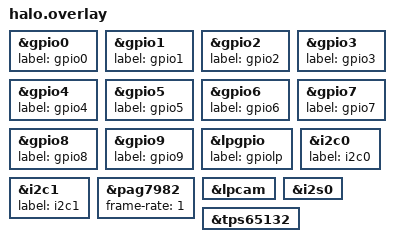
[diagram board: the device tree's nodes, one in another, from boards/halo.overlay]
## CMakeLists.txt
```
# Copyright (C) 2023 Alif Semiconductor - All Rights Reserved.
# Use, distribution and modification of this code is permitted under the
# terms stated in the Alif Semiconductor Software License Agreement
#
# You should have received a copy of the Alif Semiconductor Software
# License Agreement with this file. If not, please write to:
# contact@alifsemi.com, or visit: https://alifsemi.com/license

cmake_minimum_required(VERSION 3.20.0)
find_package(Zephyr REQUIRED HINTS $ENV{ZEPHYR_BASE})
project(halo)


FILE(GLOB app_sources src/*c)
target_sources(app PRIVATE ${app_sources})

libmpix_init(app)
```

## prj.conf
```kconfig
CONFIG_LOG=y
CONFIG_PRINTK=y
CONFIG_ASSERT=y
CONFIG_STDOUT_CONSOLE=y
CONFIG_SHELL=y
CONFIG_GPIO=y
CONFIG_GPIO_SHELL=y
CONFIG_I2C=y
CONFIG_REGULATOR=y
CONFIG_REGULATOR_SHELL=y
CONFIG_I2C_SHELL=y
CONFIG_SENSOR=y
CONFIG_SENSOR_SHELL=y
CONFIG_ADC=y
CONFIG_ADC_SHELL=y
CONFIG_FILE_SYSTEM=y
CONFIG_FILE_SYSTEM_LITTLEFS=y
CONFIG_FILE_SYSTEM_SHELL=y
CONFIG_SETTINGS_FILE_PATH="/lfs/settings"


CONFIG_MAIN_STACK_SIZE=4096
CONFIG_IDLE_STACK_SIZE=4096
CONFIG_ISR_STACK_SIZE=4096

CONFIG_PM=y
CONFIG_PM_DEVICE=y
CONFIG_COUNTER=y
CONFIG_COUNTER_RTC_SNPS_DW=y
CONFIG_COUNTER_SNPS_DW=y
```

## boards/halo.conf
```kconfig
CONFIG_I2C_DW=y
CONFIG_I2C_TARGET=y
CONFIG_I2C=y
CONFIG_I2C_DW_CLOCK_SPEED=40

# Flash layout
CONFIG_XIP=y
CONFIG_FLASH=y
CONFIG_FLASH_MAP=y
CONFIG_FLASH_PAGE_LAYOUT=y
CONFIG_MPU_ALLOW_FLASH_WRITE=y
CONFIG_HEAP_MEM_POOL_SIZE=65536

#Microphone & Speaker
CONFIG_I2S=y
CONFIG_AUDIO=y
CONFIG_MAX98357A_AUDIO=y
CONFIG_MAX98357A_AUDIO_GENERIC_API=y
CONFIG_T5838_AAD_TRIGGER=y

#Display
CONFIG_DISPLAY=y
CONFIG_CDC200=y
CONFIG_MIPI_DSI=y
CONFIG_CANVAS=y
CONFIG_FB_USES_DTCM_REGION=y

# LED
CONFIG_PWM=y
CONFIG_LED_PWM=y
CONFIG_LED_INIT_PRIORITY=50

# Camera
CONFIG_VIDEO=y
CONFIG_VIDEO_MIPI_CSI2_DW=n
CONFIG_VIDEO_BUFFER_POOL_NUM_MAX=1
CONFIG_VIDEO_BUFFER_POOL_SZ_MAX=327680
CONFIG_FB_USES_DTCM_REGION=y
CONFIG_MPIX=y
CONFIG_MPIX_HEAP_SIZE=65536

# BLE
CONFIG_BT=y
CONFIG_BT_CUSTOM=y
```

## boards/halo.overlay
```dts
/* label for it */

&gpio0 {
	label = "gpio0";
};
&gpio1 {
	label = "gpio1";
};
&gpio2 {
	label = "gpio2";
};
&gpio3 {
	label = "gpio3";
};
&gpio4 {
	label = "gpio4";
};
&gpio5 {
	label = "gpio5";
};
&gpio6 {
	label = "gpio6";
};
&gpio7 {
	label = "gpio7";
};
&gpio8 {
	label = "gpio8";
};
&gpio9 {
	label = "gpio9";
};
&lpgpio {
	label = "gpiolp";
};
&i2c0{
    label = "i2c0";
};
&i2c1{
    label = "i2c1";
};


&pag7982{
	status = "okay";
	frame-rate = <1>;
};

&lpcam {
	status = "okay";
};

&i2s0 {
	status = "okay";
};

/* The display (vga020) takes its rails from this PMIC; the board leaves it disabled. */
&tps65132 {
	status = "okay";
};
```

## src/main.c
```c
#include <errno.h>
#include <stddef.h>
#include <stdlib.h>
#include <string.h>

#include <zephyr/sys/printk.h>
#include <zephyr/sys/byteorder.h>
#include <zephyr/kernel.h>
#include <zephyr/drivers/gpio.h>
#include <zephyr/drivers/input/button.h>
//#include <t5838.h>

void button_event_cb(const struct device *dev, enum button_action action)
{
	switch (action) {
	case BUTTON_SINGLE_CLICK:
		printf("\nSingle Click: %d\n", k_uptime_get_32());
		break;
	case BUTTON_DOUBLE_CLICK:
		printf("\nDouble Click: %d\n", k_uptime_get_32());
		break;
	case BUTTON_LONG_PRESS:
		printf("\nLong Press: %d\n", k_uptime_get_32());
		break;
	case BUTTON_LONG_PRESS_LEVEL_1:
		printf("\nLong Press Level 1: %d\n", k_uptime_get_32());
		break;
	case BUTTON_LONG_PRESS_LEVEL_2:
		printf("\nLong Press Level 2: %d\n", k_uptime_get_32());
		break;
	case BUTTON_LONG_PRESS_LEVEL_3:
		printf("\nLong Press Level 3: %d\n", k_uptime_get_32());
		break;
	default:
		break;
	}
}

void t5838_cb(const struct device *dev)
{
	printf("\nT5838 interrupt triggered\n");
}

int main(void)
{
	const struct device *button = DEVICE_DT_GET(DT_ALIAS(sw0));

	button_callback_register(button, button_event_cb);

	// const struct device *t5838 = DEVICE_DT_GET(DT_NODELABEL(t5838));

	// /*AAD A CONFIGURATION */
	// struct t5838_aad_a_conf aadcfg = {
	// 	.aad_a_lpf = T5838_AAD_A_LPF_2_0kHz,
	// 	.aad_a_thr = T5838_AAD_A_THR_90dB,
	// 	.silent_period = 1000,
	// };
	// t5838_aad_a_mode_set(t5838, &aadcfg);
	// t5838_aad_wake_handler_set(t5838, t5838_cb);

	while (1) {
		k_sleep(K_SECONDS(1));
	}
	return 0;
}
```

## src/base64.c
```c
#include <math.h>
#include <string.h>

#include <zephyr/sys/util.h>

#include "base64.h"


static const char *base64_chars = "ABCDEFGHIJKLMNOPQRSTUVWXYZ"
                                  "abcdefghijklmnopqrstuvwxyz"
                                  "0123456789+/";

/**
 * @brief Base64 encode and write to a putc function
 *
 * @param input
 * @param input_size
 * @param putc_f pointer to putc function
 */
void base64_encode(const char *input, size_t input_size, void (*putc_f)(char))
{
    int i = 0;
    int j = 0;
    unsigned char char_array_3[3];
    unsigned char char_array_4[4];

    while (input_size--) {
        char_array_3[i++] = *(input++);
        if (i == 3) {
            char_array_4[0] = (char_array_3[0] & 0xfc) >> 2;
            char_array_4[1] = ((char_array_3[0] & 0x03) << 4) + ((char_array_3[1] & 0xf0) >> 4);
            char_array_4[2] = ((char_array_3[1] & 0x0f) << 2) + ((char_array_3[2] & 0xc0) >> 6);
            char_array_4[3] = char_array_3[2] & 0x3f;

            for (i = 0; (i < 4); i++) {
                putc_f(base64_chars[char_array_4[i]]);
            }
            i = 0;
        }
    }

    if (i) {
        for (j = i; j < 3; j++) {
            char_array_3[j] = '\0';
        }

        char_array_4[0] = (char_array_3[0] & 0xfc) >> 2;
        char_array_4[1] = ((char_array_3[0] & 0x03) << 4) + ((char_array_3[1] & 0xf0) >> 4);
        char_array_4[2] = ((char_array_3[1] & 0x0f) << 2) + ((char_array_3[2] & 0xc0) >> 6);
        char_array_4[3] = char_array_3[2] & 0x3f;

        for (j = 0; (j < i + 1); j++) {
            putc_f(base64_chars[char_array_4[j]]);
        }

        while ((i++ < 3)) {
            putc_f('=');
        }
    }
}

void base64_encode_chunk(const char *input, size_t input_size, void (*putc_f)(char))
{
    static char leftover[3];
    static uint8_t leftover_size = 0;

    if (input == NULL) {
        base64_encode(leftover, leftover_size, putc_f);
        leftover_size = 0;
        return;
    }

    // if we have leftover bytes, try to get N bytes from input
    // to fulfill 3 bytes chunk from base64 encoder
    if (leftover_size > 0) {
        // in case input_size is 1B and we have 1B leftover
        uint8_t to_copy = MIN((size_t)(3 - leftover_size), input_size);
        memcpy(&leftover[leftover_size], input, to_copy);
        leftover_size += to_copy;
        // if we hve not enough data to encode, break
        if (leftover_size < 3) {
            return;
        }
        base64_encode(leftover, leftover_size, putc_f);
        leftover_size = 0;
        input_size -= to_copy;
        input += to_copy;
    }

    if (input_size % 3 == 0) {
        base64_encode(input, input_size, putc_f);
    }
    else {
        leftover_size = input_size % 3;
        base64_encode(input, input_size - leftover_size, putc_f);
        memcpy(leftover, &input[input_size - leftover_size], leftover_size);
    }
}

void base64_encode_finish(void (*putc_f)(char))
{
    base64_encode_chunk(NULL, 0, putc_f);
}

/**
 * @brief Base64 encode and write to output buffer, errors on buffer overflow
 *
 * @param input
 * @param input_size
 * @param output
 * @param output_size
 * @return int number of bytes in output buffer, negative if error occured
 */
int base64_encode_buffer(const char *input, size_t input_size, char *output, size_t output_size)
{
    size_t output_size_check = floor(input_size / 3 * 4);
    size_t mod = input_size % 3;
    output_size_check += mod;

    if (output_size < output_size_check) {
        return -10;
    }

    int i = 0;
    int j = 0;
    unsigned char char_array_3[3];
    unsigned char char_array_4[4];
    size_t output_ix = 0;

    while (input_size--) {
        char_array_3[i++] = *(input++);
        if (i == 3) {
            char_array_4[0] = (char_array_3[0] & 0xfc) >> 2;
            char_array_4[1] = ((char_array_3[0] & 0x03) << 4) + ((char_array_3[1] & 0xf0) >> 4);
            char_array_4[2] = ((char_array_3[1] & 0x0f) << 2) + ((char_array_3[2] & 0xc0) >> 6);
            char_array_4[3] = char_array_3[2] & 0x3f;

            for (i = 0; (i < 4); i++) {
                output[output_ix++] = base64_chars[char_array_4[i]];
            }
            i = 0;
        }
    }

    if (i) {
        for (j = i; j < 3; j++) {
            char_array_3[j] = '\0';
        }

        char_array_4[0] = (char_array_3[0] & 0xfc) >> 2;
        char_array_4[1] = ((char_array_3[0] & 0x03) << 4) + ((char_array_3[1] & 0xf0) >> 4);
        char_array_4[2] = ((char_array_3[1] & 0x0f) << 2) + ((char_array_3[2] & 0xc0) >> 6);
        char_array_4[3] = char_array_3[2] & 0x3f;

        for (j = 0; (j < i + 1); j++) {
            output[output_ix++] = base64_chars[char_array_4[j]];
        }

        while ((i++ < 3)) {
            output[output_ix++] = '=';
        }
    }

    return output_ix;
}
```

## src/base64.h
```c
#ifndef BASE64_H
#define BASE64_H

#include <stddef.h>
#include <stdint.h>

void base64_encode(const char *input, size_t input_size, void (*putc_f)(char));
void base64_encode_chunk(const char *input, size_t input_size, void (*putc_f)(char));
void base64_encode_finish(void (*putc_f)(char));
int base64_encode_buffer(const char *input, size_t input_size, char *output, size_t output_size);

#endif
```

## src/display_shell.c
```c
#include <string.h>
#include <stdlib.h>

#include <zephyr/kernel.h>
#include <zephyr/shell/shell.h>

#if CONFIG_DISPLAY
#include <zephyr/drivers/display.h>
#include <zephyr/drivers/display/cdc200.h>
#include <zephyr/drivers/mipi_dsi/dsi_dw.h>
#include <zephyr/pm/device.h>
#include <canvas.h>

static const struct device *dsi = NULL;
static const struct device *panel = NULL;
static const struct device *display = NULL;

static Canvas canvas;

static int color_index = 0;
/* Color list */
static const Color color_list[] = {
	COLOR_HEX(0xFFFFFF), // White
	COLOR_HEX(0xFF0000), // Red
	COLOR_HEX(0x00FF00), // Green
	COLOR_HEX(0x0000FF), // Blue
	COLOR_HEX(0x000000), // Black
	COLOR_HEX(0x646464), // Gray
};
#define COLOR_COUNT (sizeof(color_list) / sizeof(color_list[0]))
#define MODE_COUNT  (COLOR_COUNT + 1)

static void update_display_color(void)
{
	canvas_clear(&canvas, color_list[color_index]);
}

void draw_grayscale_pyramid(const struct shell *sh)
{
	const int cx = LOG_WIDTH / 2;  // Center X coordinate (160)
	const int cy = LOG_HEIGHT / 2; // Center Y coordinate (120)

	const int W = LOG_WIDTH;  // Logical display width (320)
	const int H = LOG_HEIGHT; // Logical display height (240)

	// Iterate through every pixel on the screen
	for (int y = 0; y < LOG_HEIGHT; y++) {
		for (int x = 0; x < LOG_WIDTH; x++) {
			int dx = abs(x - cx); // Horizontal distance to center
			int dy = abs(y - cy); // Vertical distance to center

			// Simulate pyramid height: scale and take the max
			int dist = MAX(dx * H, dy * W);

			// Normalize distance to a grayscale range [0, 255]
			int max_dist = (W / 2) * H; // Maximum possible distance (at corners)
			uint8_t gray = (uint8_t)((dist * 255) / max_dist);
			if (gray > 255) {
				gray = 255;
			}

			// Set the pixel to the computed grayscale value
			Color color = COLOR_RGB(gray, gray, gray);
			canvas_set_pixel(&canvas, x, y, color);
		}
	}

	shell_print(sh, "Pyramid-style grayscale gradient drawn (center black, corners white)");
}

static int cmd_display_draw(const struct shell *sh, size_t argc, char *argv[])
{
	int err = 0;

	ARG_UNUSED(argc);
	ARG_UNUSED(argv);

	if (!panel) {
		shell_error(sh, "No display device found");
		return -ENODEV;
	}

	color_index = (color_index - 1 + MODE_COUNT) % MODE_COUNT;
	if (color_index < COLOR_COUNT) {
		update_display_color();
		shell_print(sh, "Color changed to index %d", color_index);
	} else {
		draw_grayscale_pyramid(sh);
	}

	return err;
}

static int cmd_get_device(const struct shell *sh, size_t argc, char *argv[])
{
	int err = 0;

	ARG_UNUSED(argc);
	ARG_UNUSED(argv);

	if (!panel) {
		shell_error(sh, "No display device found");
		return -ENODEV;
	}

	shell_print(sh, "Display Device: %s", panel->name);

	return err;
}

static int cmd_display_fill(const struct shell *sh, size_t argc, char *argv[])
{
	int err = 0;
	uint32_t color = 0;
	ARG_UNUSED(argc);
	ARG_UNUSED(argv);
	if (!panel) {
		shell_error(sh, "No display device found");
		return -ENODEV;
	}

	color = strtol(argv[1], NULL, 16);

	shell_print(sh, "Fill Color %06X", color);
	canvas_clear(&canvas, COLOR_HEX(color));

	return err;
}

static int cmd_display_brightness(const struct shell *sh, size_t argc, char *argv[])
{
	int err = 0;
	uint8_t brightness = 0;
	ARG_UNUSED(argc);
	ARG_UNUSED(argv);
	if (!panel) {
		shell_error(sh, "No display device found");
		return -ENODEV;
	}
	brightness = strtol(argv[1], NULL, 10);
	// shell_print(sh, "Brightness: %d", brightness);
	display_set_brightness(panel, brightness);
	return err;
}

static int cmd_display_init(const struct shell *sh, size_t argc, char *argv[])
{
	int err = 0;
	ARG_UNUSED(argc);
	ARG_UNUSED(argv);

	panel = DEVICE_DT_GET(DT_CHOSEN(zephyr_panel));

	if (!device_is_ready(panel)) {
		shell_error(sh, "Panel device %s not ready", panel->name);
		return -1;
	}

	dsi = DEVICE_DT_GET(DT_ALIAS(mipi_dsi));
	if (!device_is_ready(dsi)) {
		shell_error(sh, "DSI device %s not ready", dsi->name);
		return -1;
	}

	display = DEVICE_DT_GET(DT_CHOSEN(zephyr_display));
	if (!device_is_ready(display)) {
		shell_error(sh, "Display device %s not ready", display->name);
		return -1;
	}

#ifdef CONFIG_PM_DEVICE
	pm_device_action_run(panel, PM_DEVICE_ACTION_RESUME);
#endif

	if (dsi_dw_set_mode(dsi, DSI_DW_VIDEO_MODE)) {
		shell_error(sh, "DSI Host controller set to video mode.");
		return -1;
	}

	cdc200_set_enable(display, true);
	struct cdc200_fb_desc layer;
	cdc200_get_framebuffer(display, 0, &layer);
	canvas_init(&canvas, (uint8_t (*)[240][3])layer.fb_addr);
	canvas_set_font(&canvas, &Dogica8px, 1);

	err = display_blanking_off(panel);

	return err;
}

static int cmd_display_on(const struct shell *sh, size_t argc, char *argv[])
{
	int err = 0;
	ARG_UNUSED(argc);
	ARG_UNUSED(argv);
	if (!panel) {
		shell_error(sh, "No display device found");
		return -ENODEV;
	}

	err = display_blanking_off(panel);

	return err;
}

static int cmd_display_off(const struct shell *sh, size_t argc, char *argv[])
{
	int err = 0;
	ARG_UNUSED(argc);
	ARG_UNUSED(argv);
	if (!panel) {
		shell_error(sh, "No display device found");
		return -ENODEV;
	}

	err = display_blanking_on(panel);

	return err;
}

static int cmd_display_deinit(const struct shell *sh, size_t argc, char *argv[])
{
	int err = 0;
	ARG_UNUSED(argc);
	ARG_UNUSED(argv);
	if (!panel) {
		shell_error(sh, "No display device found");
		return -ENODEV;
	}

	err = display_blanking_on(panel);

	cdc200_set_enable(display, false);

#ifdef CONFIG_PM_DEVICE
	pm_device_action_run(panel, PM_DEVICE_ACTION_SUSPEND);
#endif

	return err;
}

SHELL_STATIC_SUBCMD_SET_CREATE(
	sub_display,
	SHELL_CMD_ARG(get_device, NULL, "get the display device", cmd_get_device, 1, 0),
	SHELL_CMD_ARG(init, NULL, "initialize the display device", cmd_display_init, 1, 0),
	SHELL_CMD_ARG(deinit, NULL, "deinitialize the display device", cmd_display_deinit, 1, 0),
	SHELL_CMD_ARG(fill, NULL, "fill the display with a color", cmd_display_fill, 2, 0),
	SHELL_CMD_ARG(brightness, NULL, "set the brightness of the display device",
		      cmd_display_brightness, 2, 0),
	SHELL_CMD_ARG(draw, NULL, "draw and switch color", cmd_display_draw, 1, 0),
	SHELL_CMD_ARG(on, NULL, "turn on the display", cmd_display_on, 1, 0),
	SHELL_CMD_ARG(off, NULL, "turn off the display", cmd_display_off, 1, 0),

	SHELL_SUBCMD_SET_END);

SHELL_CMD_REGISTER(display, &sub_display, "Display device commands", NULL);

#endif
```

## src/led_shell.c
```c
#include <string.h>
#include <stdlib.h>

#include <zephyr/kernel.h>
#include <zephyr/shell/shell.h>

#ifdef CONFIG_LED_PWM
#include <zephyr/device.h>
#include <zephyr/devicetree.h>
#include <errno.h>
#include <zephyr/drivers/led.h>
#include <zephyr/sys/util.h>
#include <zephyr/logging/log.h>

#define LED_PWM_NODE_ID	 DT_COMPAT_GET_ANY_STATUS_OKAY(pwm_leds)

static const struct device *led_pwm = NULL;


static int cmd_get_device(const struct shell *sh, size_t argc, char *argv[])
{
	int err = 0;

	ARG_UNUSED(argc);
	ARG_UNUSED(argv);

	if (!led_pwm) {
		shell_error(sh, "No led device found");
		return -ENODEV;
	}

	shell_print(sh, "led Device: %s", led_pwm->name);

	return err;
}

static int cmd_led_init(const struct shell *sh, size_t argc, char *argv[])
{
	int err = 0;
	ARG_UNUSED(argc);
	ARG_UNUSED(argv);

	led_pwm = DEVICE_DT_GET(LED_PWM_NODE_ID);

	if (!device_is_ready(led_pwm)) {
		shell_error(sh, "led_pwm device %s not ready", led_pwm->name);
		return -1;
	}

	return err;
}

static int cmd_led_brightness(const struct shell *sh, size_t argc, char *argv[])
{
	int err = 0;
	uint8_t brightness = 0;

	ARG_UNUSED(argc);
	ARG_UNUSED(argv);

	if (!led_pwm) {
		shell_error(sh, "No led device found");
		return -ENODEV;
	}

	brightness = strtol(argv[1], NULL, 10);
	shell_print(sh, "Brightness: %d", brightness);
	led_set_brightness(led_pwm, 0, brightness);

	return err;
}

SHELL_STATIC_SUBCMD_SET_CREATE(
	sub_led,
	SHELL_CMD_ARG(get_device, NULL, "get the led device", cmd_get_device, 1, 0),
	SHELL_CMD_ARG(init, NULL, "initialize the led device", cmd_led_init, 1, 0),
	SHELL_CMD_ARG(brightness, NULL, "set the brightness of the led device",
		      cmd_led_brightness, 2, 0),
	SHELL_SUBCMD_SET_END);

SHELL_CMD_REGISTER(led, &sub_led, "led device commands", NULL);

#endif
```

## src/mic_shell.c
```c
#include <string.h>
#include <stdlib.h>

#include <zephyr/kernel.h>
#include <zephyr/shell/shell.h>

#ifdef CONFIG_AUDIO
#include <zephyr/audio/dmic.h>
#include <t5838.h>

#define MICPHONE_NODE DT_CHOSEN(zephyr_micphone)

#if !DT_NODE_HAS_STATUS(MICPHONE_NODE, okay)
#error "Unsupported board: micphone devicetree node is not defined"
#endif

static const struct device *dev = DEVICE_DT_GET(MICPHONE_NODE);

static k_tid_t tid;
static struct k_thread micphone_thread;
static K_THREAD_STACK_DEFINE(micphone_thread_stack, 1024);
static bool is_initialized = false;
static bool is_recording = false;

#define PDM_SAMPLE_RATE  8000
#define SAMPLE_BIT_WIDTH 16
#define NUM_CHANNELS     2
#define DURATION_MS      5000
#define INTERVAL_MS      100 // 100ms interval
#define PDM_CHANNELS     (BIT(2) | BIT(3))

#define PDM_BLOCK_SIZE      (INTERVAL_MS * PDM_SAMPLE_RATE * SAMPLE_BIT_WIDTH * NUM_CHANNELS / 8 / 1000)
#define DATA_SIZE           (PDM_BLOCK_SIZE * (DURATION_MS / INTERVAL_MS))
#define MEM_SLAB_NUM_BLOCKS (DURATION_MS / INTERVAL_MS)

// static uint8_t pdm_data[DATA_SIZE];

// every 100ms allocate a block from the slab
K_MEM_SLAB_DEFINE(mem_slab, PDM_BLOCK_SIZE, MEM_SLAB_NUM_BLOCKS, 4);

static void micphone_fill(void *arg1, void *arg2, void *arg3)
{
	ARG_UNUSED(arg2);
	ARG_UNUSED(arg3);
	int err = 0;
	const struct shell *sh = (const struct shell *)arg1;
	uint32_t data;
	void *buffer;
	while (is_recording) {
		err = dmic_read(dev, 0, &buffer, &data, 200);
		if (!is_recording) {
			break;
		}
		if (err) {
			shell_error(sh, "Failed to read PDM: %d\n", err);
			return;
		}
		// shell_print(sh, "Microphne Read %d bytes", data);
		shell_print(sh, "r: %04X %04X %04X %04X %04X", *((uint16_t *)buffer),
			    *((uint16_t *)buffer + 1), *((uint16_t *)buffer + 2),
			    *((uint16_t *)buffer + 3), *((uint16_t *)buffer + 4));
		k_mem_slab_free(&mem_slab, buffer);
	}
}

static int cmd_get_device(const struct shell *sh, size_t argc, char *argv[])
{
	int err = 0;
	ARG_UNUSED(argc);
	ARG_UNUSED(argv);
	if (!dev) {
		shell_error(sh, "No micphone device found");
		return -ENODEV;
	}
	shell_print(sh, "Speaker Device: %s", dev->name);
	return err;
}

static int cmd_micphone_init(const struct shell *sh, size_t argc, char *argv[])
{
	ARG_UNUSED(argc);
	ARG_UNUSED(argv);
	if (!dev) {
		shell_error(sh, "No micphone device found");
		return -ENODEV;
	}

	struct dmic_cfg cfg;
	struct pcm_stream_cfg stream;

	stream.pcm_width = SAMPLE_BIT_WIDTH;
	stream.pcm_rate = PDM_SAMPLE_RATE;
	stream.mem_slab = &mem_slab;
	stream.block_size = PDM_BLOCK_SIZE;

	cfg.channel.req_num_streams = 1;
	cfg.channel.req_num_chan = NUM_CHANNELS;
	cfg.channel.req_chan_map_lo = PDM_CHANNELS; // PDM channels 2 and 3
	cfg.channel.req_chan_map_hi = 0;
	cfg.streams = &stream;

	int rc = dmic_configure(dev, &cfg);
	if (rc < 0) {
		shell_error(sh, "Failed to configure PDM: %d", rc);
		return rc;
	}

	dmic_set_gain(dev, 5);

	is_initialized = true;
	is_recording = false;
	return 0;
}

static int cmd_micphone_deinit(const struct shell *sh, size_t argc, char *argv[])
{
	int err = 0;
	ARG_UNUSED(argc);
	ARG_UNUSED(argv);
	if (!dev) {
		shell_error(sh, "No micphone device found");
		return -ENODEV;
	}
	err = dmic_trigger(dev, DMIC_TRIGGER_STOP);
	if (err) {
		shell_error(sh, "Failed to start PWM audio: %d\n", err);
		return err;
	}
	is_initialized = false;
	is_recording = false;
	return 0;
}

static int cmd_micphone_record(const struct shell *sh, size_t argc, char *argv[])
{
	int err = 0;
	ARG_UNUSED(argc);
	ARG_UNUSED(argv);
	if (!dev) {
		shell_error(sh, "No micphone device found");
		return -ENODEV;
	}

	if (!is_initialized) {
		shell_error(sh, "Speaker not initialized\n");
		return 0;
	}

	if (is_recording) {
		shell_error(sh, "Already playing\n");
		return 0;
	}

	err = dmic_trigger(dev, DMIC_TRIGGER_START);
	if (err) {
		shell_error(sh, "Failed to start PWM audio: %d\n", err);
		return err;
	}

	is_recording = true;

	tid = k_thread_create(&micphone_thread, micphone_thread_stack,
			      K_THREAD_STACK_SIZEOF(micphone_thread_stack), micphone_fill, (void *)sh, NULL,
			      NULL, K_PRIO_COOP(7), 0, K_NO_WAIT);

	return 0;
}

static int cmd_micphone_stop(const struct shell *sh, size_t argc, char *argv[])
{
	int err = 0;
	ARG_UNUSED(argc);
	ARG_UNUSED(argv);
	if (!dev) {
		shell_error(sh, "No micphone device found");
		return -ENODEV;
	}

	if (!is_initialized) {
		shell_error(sh, "Speaker not initialized\n");
		return 0;
	}

	if (!is_recording) {
		shell_error(sh, "Not playing\n");
		return 0;
	}

	err = dmic_trigger(dev, DMIC_TRIGGER_STOP);
	if (err) {
		shell_error(sh, "Failed to stop PWM audio: %d\n", err);
		return err;
	}

	is_recording = false;
	return 0;
}

SHELL_STATIC_SUBCMD_SET_CREATE(
	sub_micphone,
	SHELL_CMD_ARG(get_device, NULL, "get the micphone device", cmd_get_device, 1, 0),
	SHELL_CMD_ARG(init, NULL, "initialize the micphone device", cmd_micphone_init, 1, 0),
	SHELL_CMD_ARG(deinit, NULL, "deinitialize the micphone device", cmd_micphone_deinit, 1, 0),
	SHELL_CMD_ARG(record, NULL, "start recording a sound", cmd_micphone_record, 1, 0),
	SHELL_CMD_ARG(stop, NULL, "stop recording a sound", cmd_micphone_stop, 1, 0),
	SHELL_SUBCMD_SET_END);

SHELL_CMD_REGISTER(micphone, &sub_micphone, "Speaker commands", NULL);

#endif // CONFIG_AUDIO
```

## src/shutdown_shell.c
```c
#include <string.h>
#include <stdlib.h>

#include <zephyr/kernel.h>
#include <zephyr/sys/reboot.h>
#include <zephyr/shell/shell.h>
#include <zephyr/drivers/sm/sm.h>

const struct device *sm = NULL;

static int cmd_shutdown(const struct shell *sh, size_t argc, char *argv[])
{
	int err = 0;

	ARG_UNUSED(argc);
	ARG_UNUSED(argv);

	sm = DEVICE_DT_GET(DT_ALIAS(shutdown));

	if (!device_is_ready(sm)) {
		shell_error(sh, "sm device %s not ready", sm->name);
		return -1;
	}

	shell_print(sh, "Shutting down - entering ship mode");

	shutdown(sm);

	return err;
}

static int cmd_reboot(const struct shell *sh, size_t argc, char *argv[])
{
	ARG_UNUSED(argc);
	ARG_UNUSED(argv);

	shell_print(sh, "Rebooting system...");
	sys_reboot(SYS_REBOOT_COLD);

	return 0;
}

SHELL_CMD_REGISTER(reboot, NULL, "reboot", cmd_reboot);
SHELL_CMD_REGISTER(shutdown, NULL, "shutdown", cmd_shutdown);
```

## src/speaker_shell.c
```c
#include <string.h>
#include <stdlib.h>

#include <zephyr/kernel.h>
#include <zephyr/shell/shell.h>
#include <zephyr/logging/log.h>


#ifdef CONFIG_AUDIO
#include <zephyr/drivers/audio.h>
#include "audio.h"

LOG_MODULE_REGISTER(speaker_shell, LOG_LEVEL_DBG);

#define SPEAKER_NODE DT_CHOSEN(zephyr_speaker)

#if !DT_NODE_HAS_STATUS(SPEAKER_NODE, okay)
#error "Unsupported board: speaker devicetree node is not defined"
#endif

static const struct device *dev = DEVICE_DT_GET(SPEAKER_NODE);

static k_tid_t tid;
static struct k_thread speaker_thread;
static K_THREAD_STACK_DEFINE(speaker_thread_stack, 1024);
static bool is_initialized = false;
static bool is_playing = false;
static bool is_continuous = false;
static uint8_t *_file = NULL;
static uint32_t _file_size = 0;

static void speaker_fill(void *arg1, void *arg2, void *arg3)
{
	ARG_UNUSED(arg2);
	ARG_UNUSED(arg3);
	int err = 0;
	const struct shell *sh = (const struct shell *)arg1;

	uint32_t remaining = _file_size;
	while (is_playing) {
		size_t bytes_written = 0;
		err = audio_write(dev, _file + _file_size - remaining, remaining,
				  &bytes_written, K_MSEC(1000));
		if (err != 0 && err != -ETIMEDOUT) {
			shell_error(sh, "Failed to write to audio device: %d\n", err);
			return;
		}
		remaining -= bytes_written;
		LOG_DBG("%d/%d %d bytes written", _file_size - remaining, _file_size, bytes_written);
		if (remaining == 0) {
			if(is_continuous) {
				remaining = _file_size;
				LOG_INF("Restarting audio playback (continuous mode)");
			}
			else{
				is_playing = false;
				LOG_INF("Audio playback completed");
			}
		}
		/* Small delay to avoid overwhelming the system */
		k_sleep(K_MSEC(10));
	}
}

static int cmd_get_device(const struct shell *sh, size_t argc, char *argv[])
{
	int err = 0;
	ARG_UNUSED(argc);
	ARG_UNUSED(argv);
	if (!dev) {
		shell_error(sh, "No speaker device found");
		return -ENODEV;
	}
	shell_print(sh, "Speaker Device: %s", dev->name);
	return err;
}

static int cmd_speaker_init(const struct shell *sh, size_t argc, char *argv[])
{
	int err = 0;
	ARG_UNUSED(argc);
	ARG_UNUSED(argv);
	
	if (!device_is_ready(dev)) {
		shell_error(sh, "Speaker device not ready");
		return -ENODEV;
	}

	/* Configure audio stream using generic interface */
	struct audio_config config = {
		.sample_rate = 8000,
		.bits_per_sample = 16,
		.channels = AUDIO_MONO,
		.is_signed = true,
	};

	err = audio_configure(dev, &config);
	if (err) {
		shell_error(sh, "Failed to configure audio: %d\n", err);
		return err;
	}

	/* Set default volume */
	err = audio_set_volume(dev, 75);
	if (err) {
		shell_warn(sh, "Failed to set volume (may not be supported): %d\n", err);
		/* Continue anyway as volume control may not be supported */
	}

	is_initialized = true;
	is_playing = false;

	shell_print(sh, "Speaker initialized successfully");
	return 0;
}

static int cmd_speaker_deinit(const struct shell *sh, size_t argc, char *argv[])
{
	int err = 0;
	ARG_UNUSED(argc);
	ARG_UNUSED(argv);
	
	if (!device_is_ready(dev)) {
		shell_error(sh, "Speaker device not ready");
		return -ENODEV;
	}
	
	/* Stop audio playback if currently playing */
	if (is_playing) {
		err = audio_trigger(dev, AUDIO_TRIGGER_STOP);
		if (err) {
			shell_error(sh, "Failed to stop audio: %d\n", err);
			return err;
		}
		is_playing = false;
	}
	
	is_initialized = false;
	shell_print(sh, "Speaker deinitialized successfully");
	return 0;
}

static int cmd_speaker_play(const struct shell *sh, size_t argc, char *argv[])
{
	int err = 0;
	ARG_UNUSED(argc);
	ARG_UNUSED(argv);
	
	if (!device_is_ready(dev)) {
		shell_error(sh, "Speaker device not ready");
		return -ENODEV;
	}

	if (!is_initialized) {
		shell_error(sh, "Speaker not initialized\n");
		return -EINVAL;
	}

	if (is_playing) {
		shell_error(sh, "Already playing\n");
		return -EALREADY;
	}

	int file = atoi(argv[1]);
	
	if (argc == 3) {
		is_continuous = true;
		shell_print(sh, "Continuous playback mode enabled");
	} else {
		is_continuous = false;
	}

	/* Start audio playback using generic interface */
	err = audio_trigger(dev, AUDIO_TRIGGER_START);
	if (err) {
		shell_error(sh, "Failed to start audio: %d\n", err);
		return err;
	}

	/* Select audio file based on parameter */
	if (file % 2 == 0) {
		_file = (uint8_t *)_acfemale_w1_8k_16bit_EQ7;
		_file_size = sizeof(_acfemale_w1_8k_16bit_EQ7);
		shell_print(sh, "Playing female voice sample");
	} else if(file % 2 == 1) {
		_file = (uint8_t *)_acmono_8k_16bit_1k_wave;
		_file_size = sizeof(_acmono_8k_16bit_1k_wave);
		shell_print(sh, "Playing mono sine wave");
	}

	is_playing = true;

	tid = k_thread_create(&speaker_thread, speaker_thread_stack,
			      K_THREAD_STACK_SIZEOF(speaker_thread_stack), 
			      speaker_fill, (void *)sh, NULL,
			      NULL, K_PRIO_COOP(7), 0, K_NO_WAIT);

	shell_print(sh, "Audio playback started");
	return 0;
}

static int cmd_speaker_stop(const struct shell *sh, size_t argc, char *argv[])
{
	int err = 0;
	ARG_UNUSED(argc);
	ARG_UNUSED(argv);
	
	if (!device_is_ready(dev)) {
		shell_error(sh, "Speaker device not ready");
		return -ENODEV;
	}

	if (!is_initialized) {
		shell_error(sh, "Speaker not initialized\n");
		return -EINVAL;
	}

	if (!is_playing) {
		shell_error(sh, "Not playing\n");
		return -EALREADY;
	}

	/* Stop the playback thread first */
	is_playing = false;

	/* Stop audio using generic interface */
	err = audio_trigger(dev, AUDIO_TRIGGER_STOP);
	if (err) {
		shell_error(sh, "Failed to stop audio: %d\n", err);
		return err;
	}

	shell_print(sh, "Audio playback stopped");
	return 0;
}
static int cmd_speaker_volume(const struct shell *sh, size_t argc, char *argv[])
{
	int err = 0;
	ARG_UNUSED(argc);
	ARG_UNUSED(argv);
	
	if (!device_is_ready(dev)) {
		shell_error(sh, "Speaker device not ready");
		return -ENODEV;
	}

	int volume = atoi(argv[1]);
	if (volume < 0 || volume > 100) {
		shell_error(sh, "Volume must be between 0 and 100");
		return -EINVAL;
	}

	/* Set volume using generic interface */
	err = audio_set_volume(dev, volume);
	if (err) {
		shell_error(sh, "Failed to set volume: %d (may not be supported)\n", err);
		return err;
	}
	
	shell_print(sh, "Volume set to %d", volume);
	return 0;
}

SHELL_STATIC_SUBCMD_SET_CREATE(
	sub_speaker,
	SHELL_CMD_ARG(get_device, NULL, "get the speaker device", cmd_get_device, 1, 0),
	SHELL_CMD_ARG(init, NULL, "initialize the speaker device with generic audio interface", cmd_speaker_init, 1, 0),
	SHELL_CMD_ARG(deinit, NULL, "deinitialize the speaker device", cmd_speaker_deinit, 1, 0),
	SHELL_CMD_ARG(play, NULL, "play audio file (file_number [continuous])", cmd_speaker_play, 2, 1),
	SHELL_CMD_ARG(stop, NULL, "stop playing audio", cmd_speaker_stop, 1, 0),
	SHELL_CMD_ARG(volume, NULL, "set the volume of the speaker device (0-100)", cmd_speaker_volume, 2,
		      0),
	SHELL_SUBCMD_SET_END);

SHELL_CMD_REGISTER(speaker, &sub_speaker, "Generic Audio Interface Speaker Commands", NULL);

#endif
```

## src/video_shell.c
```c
#include <stdio.h>
#include <string.h>
#include <stdlib.h>

#if CONFIG_VIDEO

#include <zephyr/drivers/gpio.h>
#include <zephyr/shell/shell.h>
#include <zephyr/drivers/video.h>
#include <zephyr/pm/device.h>

#include <mpix/image.h>
#include <mpix/stats.h>
#include <mpix/auto.h>
#include <mpix/print.h>

#include "base64.h"

#define VIDEO_NODE DT_CHOSEN(zephyr_video)

#if !DT_NODE_HAS_STATUS(VIDEO_NODE, okay)
#error "Unsupported board: video devicetree node is not defined"
#endif

static const struct device *dev = DEVICE_DT_GET(VIDEO_NODE);
static int max_frames = 0;
static int frame = 0;
static bool is_initialized = false;
static bool convert = false;
static struct video_caps caps;

#define VIDEO_THREAD_STACK_SIZE 4096
static k_tid_t tid;
static struct k_thread video_thread;
K_THREAD_STACK_DEFINE(video_thread_stack, VIDEO_THREAD_STACK_SIZE);

struct video_buffer *buffers[1], *vbuf;
struct video_format fmt = {0};
uint8_t preview_buffer[100 * 1024];

void putc_f(char c)
{
	printf("%c", c);
}

static int libmpix_process(const struct shell *sh, struct video_buffer *vbuf_in,
			   struct video_format *fmt_in)
{
	struct mpix_image img = {};
	struct mpix_stats stats = {};
	struct mpix_auto_ctrls ctrls = {};
	struct mpix_format fmt = {};

	fmt.width = fmt_in->width;
	fmt.height = fmt_in->height;
	fmt.fourcc = MPIX_FMT_SBGGR8;

	/* Open the video buffer as an mpix image */
	mpix_image_from_buf(&img, vbuf_in->buffer, vbuf_in->bytesused, &fmt);

	/* Auto Operations */
	mpix_image_stats(&img, &stats);
	mpix_auto_black_level(&ctrls, &stats);
	mpix_auto_white_balance(&ctrls, &stats);

	/* Add the operations to the pipeline */
	mpix_image_debayer(&img, 3);
	mpix_image_correct_black_level(&img);
	mpix_image_correct_white_balance(&img);
	mpix_image_jpeg_encode(&img);

	mpix_image_ctrl_value(&img, MPIX_CID_BLACK_LEVEL, ctrls.black_level);
	mpix_image_ctrl_value(&img, MPIX_CID_RED_BALANCE, ctrls.red_balance_q10);
	mpix_image_ctrl_value(&img, MPIX_CID_BLUE_BALANCE, ctrls.blue_balance_q10);
	mpix_image_ctrl_value(&img, MPIX_CID_JPEG_QUALITY, MPIX_JPEG_QUALITY_DEFAULT);

	/* Convert the image and store it into the output buffer */
	uint32_t start = k_uptime_get_32();
	if (mpix_image_to_buf(&img, preview_buffer, sizeof(preview_buffer)) != 0) {
		shell_error(sh, "Failed to convert the image to JPEG");
		return -1;
	}
	uint32_t end = k_uptime_get_32();
	shell_print(sh, "Image converted to JPEG in %u ms", end - start);
	int data_size = mpix_ring_total_used(&img.last_op->ring);

	printf("\nJPEG FILE:\n");
	base64_encode((const char *)preview_buffer, data_size, putc_f);
	printf("\nJPEG END\n");
	printf("use libmpix_process, size: %d\n", data_size);

	mpix_image_free(&img);

	return 0;
}

static void video_cb(void *arg1, void *arg2, void *arg3)
{
	ARG_UNUSED(arg2);
	ARG_UNUSED(arg3);
	int ret = 0;
	const struct shell *sh = (const struct shell *)arg1;

	while (1) {
		ret = video_dequeue(dev, VIDEO_EP_OUT, &vbuf, K_FOREVER);
		if (ret != 0) {
			shell_error(sh, "Failed to dequeue the output buffer into %s", dev->name);
			break;
		}

		frame++;

		if (convert) {
			libmpix_process(sh, vbuf, &fmt);
		} else {
			shell_print(sh, "Got frame %u! size: %u; timestamp %u ms", frame,
				    vbuf->bytesused, vbuf->timestamp);
		}

		if (frame < max_frames || max_frames == -1) {
			ret = video_enqueue(dev, VIDEO_EP_OUT, vbuf);
			if (ret != 0) {
				shell_error(sh, "Failed to enqueue the input buffer into %s",
					    dev->name);
				break;
			}
			ret = video_stream_start(dev);
			if (ret != 0) {
				shell_error(sh, "Failed to start the video stream");
				break;
			}

		} else {
			ret = video_stream_stop(dev);
			shell_print(sh, "Capturing stopped");
		}
	}
}

static int cmd_get_device(const struct shell *sh, size_t argc, char *argv[])
{
	int err = 0;

	ARG_UNUSED(argc);
	ARG_UNUSED(argv);

	if (!dev) {
		shell_error(sh, "No video device found");
		return -ENODEV;
	}

	shell_print(sh, "Video Device: %s", dev->name);

	return err;
}

static int cmd_video_init(const struct shell *sh, size_t argc, char *argv[])
{
	int err = 0;
	int i = 0;
	size_t bsize = 0;
	ARG_UNUSED(argc);
	ARG_UNUSED(argv);

	if (is_initialized) {
		shell_error(sh, "Video device is already initialized");
		return -ENODEV;
	}

	if (!dev) {
		shell_error(sh, "No video device found");
		return -ENODEV;
	}

#ifdef CONFIG_PM_DEVICE
	pm_device_action_run(dev, PM_DEVICE_ACTION_RESUME);
#endif

	if (video_get_caps(dev, VIDEO_EP_OUT, &caps)) {
		shell_error(sh, "Unable to retrieve video capabilities");
		return -1;
	}

	while (caps.format_caps[i].pixelformat) {
		const struct video_format_cap *fcap = &caps.format_caps[i];
		/* fourcc to string */
		shell_print(sh,
			    "  %c%c%c%c width (min, max, step)[%u; %u; %u] "
			    "height (min, max, step)[%u; %u; %u]",
			    (char)fcap->pixelformat, (char)(fcap->pixelformat >> 8),
			    (char)(fcap->pixelformat >> 16), (char)(fcap->pixelformat >> 24),
			    fcap->width_min, fcap->width_max, fcap->width_step, fcap->height_min,
			    fcap->height_max, fcap->height_step);

		if (fcap->pixelformat == VIDEO_PIX_FMT_BGGR8) {
			fmt.pixelformat = VIDEO_PIX_FMT_BGGR8;
			fmt.width = fcap->width_min;
			fmt.height = fcap->height_min;
			fmt.pitch = fcap->width_min;
		}
		i++;
	}

	if (fmt.pixelformat != VIDEO_PIX_FMT_BGGR8) {
		shell_error(sh, "Desired Pixel format is not supported.");
		return -1;
	}

	err = video_set_format(dev, VIDEO_EP_OUT, &fmt);
	if (err) {
		shell_error(sh, "Failed to set video format. ret - %d", err);
		return err;
	}

	bsize = fmt.pitch * fmt.height;

	shell_print(sh, "- format: %c%c%c%c %ux%u", (char)fmt.pixelformat,
		    (char)(fmt.pixelformat >> 8), (char)(fmt.pixelformat >> 16),
		    (char)(fmt.pixelformat >> 24), fmt.width, fmt.height);

	for (i = 0; i < ARRAY_SIZE(buffers); i++) {
		buffers[i] = video_buffer_alloc(bsize);
		if (buffers[i] == NULL) {
			shell_error(sh, "Unable to alloc video buffer");
			return -1;
		}

		/* Allocated Buffer Information */
		shell_print(sh, "- addr - 0x%x, size - %d, bytesused - %d",
			    (uint32_t)buffers[i]->buffer, bsize, buffers[i]->bytesused);
	}

	tid = k_thread_create(&video_thread, video_thread_stack,
			      K_THREAD_STACK_SIZEOF(video_thread_stack), video_cb, (void *)sh, NULL,
			      NULL, K_PRIO_COOP(7), 0, K_NO_WAIT);

	is_initialized = true;

	return err;
}

static int cmd_video_deinit(const struct shell *sh, size_t argc, char *argv[])
{
	int err = 0;
	ARG_UNUSED(argc);
	ARG_UNUSED(argv);
	if (!dev) {
		shell_error(sh, "No video device found");
		return -ENODEV;
	}

	if (!is_initialized) {
		shell_error(sh, "Video device is not initialized");
		return -ENODEV;
	}

	video_flush(dev, VIDEO_EP_OUT, false);

	err = video_stream_stop(dev);
	if (err) {
		shell_error(sh, "Unable to stop capture (interface). ret - %d", err);
		return err;
	}

	for (int i = 0; i < ARRAY_SIZE(buffers); i++) {
		video_buffer_release(buffers[i]);
	}

#ifdef CONFIG_PM_DEVICE
	pm_device_action_run(dev, PM_DEVICE_ACTION_SUSPEND);
#endif

	is_initialized = false;
	return err;
}

static int cmd_video_take(const struct shell *sh, size_t argc, char *argv[])
{
	int err = 0;
	int num = strtol(argv[1], NULL, 10);
	int show = strtol(argv[2], NULL, 10);
	if (!dev) {
		shell_error(sh, "No video device found");
		return -ENODEV;
	}
	if (!is_initialized) {
		shell_error(sh, "Video device is not initialized");
		return -ENODEV;
	}

	frame = 0;
	max_frames = num;

	for (int i = 0; i < ARRAY_SIZE(buffers); i++) {
		err = video_enqueue(dev, VIDEO_EP_OUT, buffers[i]);
		if (err) {
			shell_error(sh, "Unable to enqueue video buf");
			return -1;
		}
	}

	convert = show == 1;

	err = video_stream_start(dev);
	if (err) {
		shell_error(sh, "Unable to start capture (interface). ret - %d", err);
		return -1;
	}

	shell_print(sh, "Taking %d pictures", max_frames);

	return err;
}

SHELL_STATIC_SUBCMD_SET_CREATE(
	sub_video, SHELL_CMD_ARG(get_device, NULL, "get the video device", cmd_get_device, 1, 0),
	SHELL_CMD_ARG(init, NULL, "initialize the video device", cmd_video_init, 1, 0),
	SHELL_CMD_ARG(deinit, NULL, "deinitialize the video device", cmd_video_deinit, 1, 0),
	SHELL_CMD_ARG(take, NULL, "take n pictures (-1: infinite 0: stop) show: take 10 1",
		      cmd_video_take, 3, 0),
	SHELL_SUBCMD_SET_END);

SHELL_CMD_REGISTER(video, &sub_video, "video device commands", NULL);

#endif
```
